# DECODER0_MTX_CORE register map
Vendor: Texas Instruments
Peripheral module from a debugger description file (folder J7ES).
Registers are 32-bit, read-write, reset values left out (the file's numbers can be read two ways) unless marked. A register's access mark holds for its fields unless they carry their own. Offsets are as the file gives them; lines under a group give offsets from that group; [hi:lo] are bit positions; {n}, {i} and the like mark numbered series; 'fields as' and 'values as' point back to an identical list; <NAME> marks a mode.

## DECODER0_MTX_CORE
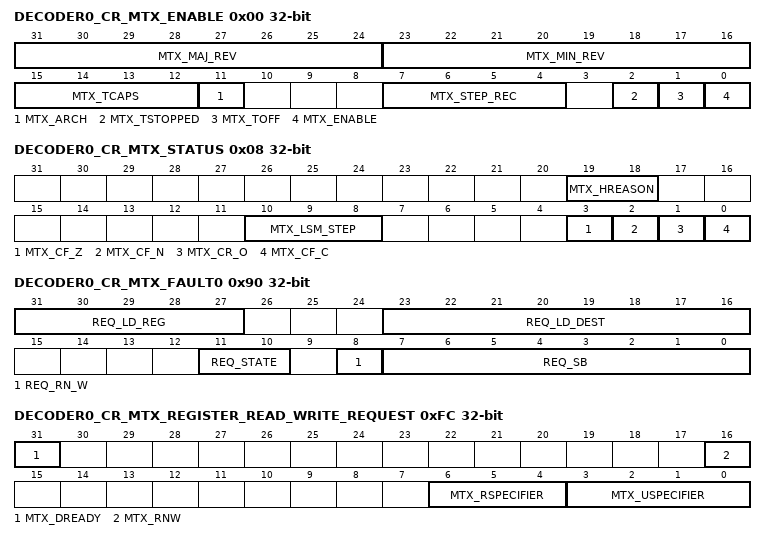
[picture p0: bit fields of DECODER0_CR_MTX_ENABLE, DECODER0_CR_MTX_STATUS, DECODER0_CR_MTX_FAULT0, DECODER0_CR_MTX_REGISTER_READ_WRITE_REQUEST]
0x00 DECODER0_CR_MTX_ENABLE
  [31:24] MTX_MAJ_REV, [23:16] MTX_MIN_REV, [15:12] MTX_TCAPS, [11] MTX_ARCH, [7:4] MTX_STEP_REC, [2] MTX_TSTOPPED, [1] MTX_TOFF, [0] MTX_ENABLE
0x08 DECODER0_CR_MTX_STATUS
  [19:18] MTX_HREASON, [10:8] MTX_LSM_STEP, [3] MTX_CF_Z, [2] MTX_CF_N, [1] MTX_CR_O, [0] MTX_CF_C
0x80 DECODER0_CR_MTX_KICK
  [15:0] MTX_KICK
0x88 DECODER0_CR_MTX_KICKI
  [15:0] MTX_KICKI
0x90 DECODER0_CR_MTX_FAULT0
  [31:27] REQ_LD_REG, [23:16] REQ_LD_DEST, [11:10] REQ_STATE, [8] REQ_RN_W, [7:0] REQ_SB
0xF8 DECODER0_CR_MTX_REGISTER_READ_WRITE_DATA
  [31:0] MTX_RWDATA
0xFC DECODER0_CR_MTX_REGISTER_READ_WRITE_REQUEST
  [31] MTX_DREADY, [16] MTX_RNW, [6:4] MTX_RSPECIFIER, [3:0] MTX_USPECIFIER
0x100 DECODER0_CR_MTX_RAM_ACCESS_DATA_EXCHANGE
  [31:0] MTX_MCMDATAX
0x104 DECODER0_CR_MTX_RAM_ACCESS_DATA_TRANSFER
  [31:0] MTX_MCMDATAT
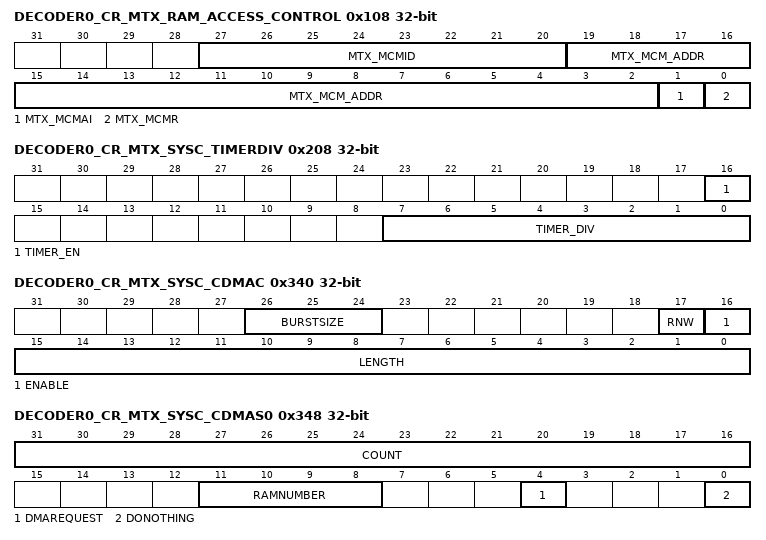
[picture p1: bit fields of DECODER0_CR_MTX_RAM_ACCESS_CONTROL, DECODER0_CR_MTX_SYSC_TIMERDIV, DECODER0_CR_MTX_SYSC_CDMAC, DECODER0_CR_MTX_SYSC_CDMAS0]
0x108 DECODER0_CR_MTX_RAM_ACCESS_CONTROL
  [27:20] MTX_MCMID, [19:2] MTX_MCM_ADDR, [1] MTX_MCMAI, [0] MTX_MCMR
0x10C DECODER0_CR_MTX_RAM_ACCESS_STATUS
  [0] MTX_MTX_MCM_STAT
0x200 DECODER0_CR_MTX_SOFT_RESET
  [0] MTX_RESET
0x208 DECODER0_CR_MTX_SYSC_TIMERDIV
  [16] TIMER_EN — Timer enable.
  [7:0] TIMER_DIV — Timer Divider Control.
0x340 DECODER0_CR_MTX_SYSC_CDMAC
  [26:24] BURSTSIZE — This specifies the burst size used for DMA transfers.
  [17] RNW — This should be set to '0' to write to the core memories, or '1' to read from the core memories.
  [16] ENABLE — Causes a transfer to begin next time the transfer state machine is ready.
  [15:0] LENGTH — This specifies the transfer size of the DMA operation in terms of
0x344 DECODER0_CR_MTX_SYSC_CDMAA
  [25:2] CDMAA_ADDRESS — This is the core DMA transfer start address.
0x348 DECODER0_CR_MTX_SYSC_CDMAS0 ro
  [31:16] COUNT — This is the count of remaining items to be transferred.
  [11:8] RAMNUMBER — This indicates the current RAM number that a DMA transfer is targeting.
  [4] DMAREQUEST — This is a duplicate of the DMA request hardware line from this block to the DMA controller and may be needed if data transfer is from a host processor rather than the DMA controller.
  [0] DONOTHING — Transfer State == 'do_nothing'.
0x34C DECODER0_CR_MTX_SYSC_CDMAS1 ro
  [25:2] CDMAS1_ADDRESS — This is the current core DMA transfer address.
0x350 DECODER0_CR_MTX_SYSC_CDMAT
  [31:0] TRANSFERDATA — Data to be written to core RAMs [when writing only], or data read from core RAMs [when reading only].
